AUTOSAR XML (schema 00048)
standard types defined: uint8, sint8
package /System
  system System: category=SYSTEM_EXTRACT
package /Ecus
  6 x ecu instance:
    Ecu0
      can communication controller CanCtrl0
      can communication connector Can0Conn: comm-controller=CanCtrl0
    Ecu1
      can communication controller CanCtrl1
      can communication connector Can1Conn: comm-controller=CanCtrl1
    Ecu2
    Ecu3
    EthServer
      ethernet communication controller EthCtrl
        coupling port EthCtrl_CouplingPort
      ethernet communication connector EthConn: category=WIRED, comm-controller=EthServer/EthCtrl
    EthClient
      ethernet communication controller EthCtrl
        coupling port EthCtrl_CouplingPort
      ethernet communication connector EthConn: category=WIRED, comm-controller=EthClient/EthCtrl
package /Units
  unit degC: display-name=degC
package /Transformers
  data transformation set E2E
    transformation technology E2E_0:
      buffer-properties={header-length=96, in-place=true}
      has-internal-state=true
      needs-original-data=false
      protocol=E2E
      end-to-end-transformation-description{max-delta-counter=1, max-error-state-init=0, max-error-state-invalid=0, max-error-state-valid=0, max-no-new-or-repeated-data=2, min-ok-state-init=1, min-ok-state-invalid=1, min-ok-state-valid=1, offset=0, profile-behavior=R-4--2, profile-name=PROFILE_04, upper-header-bits-to-shift=0, window-size-init=3, window-size-invalid=3, window-size-valid=3}
      transformer-class=SAFETY
      version=1.0.0
    transformation technology E2E_1:
      buffer-properties={header-length=24, in-place=true}
      has-internal-state=true
      needs-original-data=false
      protocol=E2E
      end-to-end-transformation-description{max-delta-counter=1, max-error-state-init=0, max-error-state-invalid=0, max-error-state-valid=0, max-no-new-or-repeated-data=2, min-ok-state-init=1, min-ok-state-invalid=1, min-ok-state-valid=1, offset=8, profile-behavior=R-4--2, profile-name=PROFILE_05, upper-header-bits-to-shift=8, window-size-init=3, window-size-invalid=3, window-size-valid=3}
      transformer-class=SAFETY
      version=1.0.0
package /Can0
  can cluster Can0: baudrate=500000, protocol-name=CAN
    can physical channel Can0Ch: comm-connectors=Can0Conn
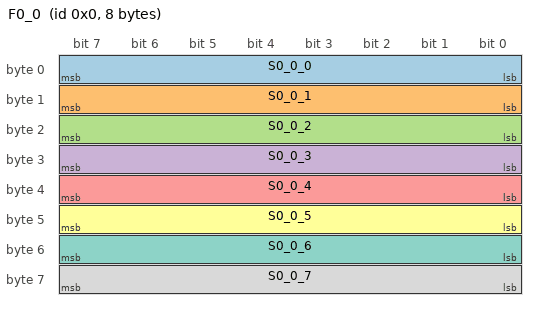
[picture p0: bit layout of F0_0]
      frame F0_0: id 0x0, frame-length=8, can-addressing-mode=STANDARD, can-frame-rx-behavior=CAN-20, can-frame-tx-behavior=CAN-20
        pdu P0_0: length=8, transmission-mode-true-timing=cyclic-timing=time-period=0.01
          signal S0_0_0: start 0, 8 bit, little-endian, data-type-policy=OVERRIDE, base-type=uint8, end-to-end-transformation-i-signal-props{transformer=E2E_0, data-ids=256}, compu {identical}, transfer-property=PENDING
          signal S0_0_1: start 8, 8 bit, little-endian, data-type-policy=OVERRIDE, base-type=uint8, compu {phys=raw*0.5-40 for raw 0..255}, range phys -40..87.5, unit=degC, transfer-property=PENDING
          signal S0_0_2: start 16, 8 bit, little-endian, data-type-policy=OVERRIDE, base-type=uint8, compu {0=Off, 1=On, 2=Error, 3=SNA}, transfer-property=PENDING
          signal S0_0_3: start 24, 8 bit, little-endian, data-type-policy=OVERRIDE, base-type=uint8, compu {phys=raw for raw 0..99, phys=raw*2-100 for raw 100..255}, transfer-property=PENDING
          signal S0_0_4: start 32, 8 bit, little-endian, data-type-policy=OVERRIDE, base-type=sint8, compu {phys=(1+2*raw)/(4+0.5*raw) for raw -128..127}, transfer-property=PENDING
          signal S0_0_5: start 40, 8 bit, little-endian, data-type-policy=OVERRIDE, base-type=uint8, compu {0=0, 1=10, 2=25, 3=60}, transfer-property=PENDING
          signal S0_0_6: start 48, 8 bit, little-endian, data-type-policy=OVERRIDE, base-type=uint8, compu {mask 1: 1=Left, mask 2: 2=Right, mask 4: 4=Hazard}, transfer-property=PENDING
          signal S0_0_7: start 56, 8 bit, little-endian, data-type-policy=OVERRIDE, base-type=uint8, compu {phys=raw*0.25 for raw 0..250, 254=Init, 255=SNA}, transfer-property=PENDING
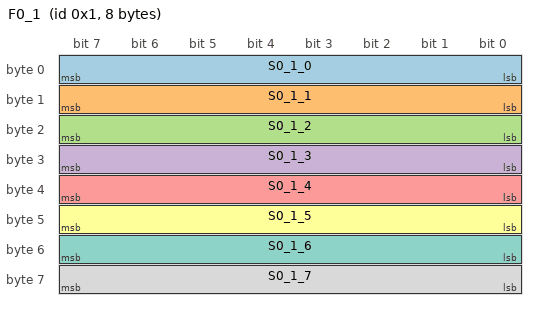
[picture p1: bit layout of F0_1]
      frame F0_1: id 0x1, frame-length=8, can-addressing-mode=STANDARD, can-frame-rx-behavior=CAN-20, can-frame-tx-behavior=CAN-20
        pdu P0_1: length=8, transmission-mode-true-timing=cyclic-timing=time-period=0.02
          signal S0_1_0: start 7, 8 bit, big-endian, data-type-policy=OVERRIDE, base-type=uint8, end-to-end-transformation-i-signal-props{transformer=E2E_1, data-ids=257}, compu {identical}, transfer-property=PENDING
          signal S0_1_1: start 15, 8 bit, big-endian, data-type-policy=OVERRIDE, base-type=uint8, compu {phys=raw*0.5-40 for raw 0..255}, range phys -40..87.5, unit=degC, transfer-property=PENDING
          signal S0_1_2: start 23, 8 bit, big-endian, data-type-policy=OVERRIDE, base-type=uint8, compu {0=Off, 1=On, 2=Error, 3=SNA}, transfer-property=PENDING
          signal S0_1_3: start 31, 8 bit, big-endian, data-type-policy=OVERRIDE, base-type=uint8, compu {phys=raw for raw 0..99, phys=raw*2-100 for raw 100..255}, transfer-property=PENDING
          signal S0_1_4: start 39, 8 bit, big-endian, data-type-policy=OVERRIDE, base-type=sint8, compu {phys=(1+2*raw)/(4+0.5*raw) for raw -128..127}, transfer-property=PENDING
          signal S0_1_5: start 47, 8 bit, big-endian, data-type-policy=OVERRIDE, base-type=uint8, compu {0=0, 1=10, 2=25, 3=60}, transfer-property=PENDING
          signal S0_1_6: start 55, 8 bit, big-endian, data-type-policy=OVERRIDE, base-type=uint8, compu {mask 1: 1=Left, mask 2: 2=Right, mask 4: 4=Hazard}, transfer-property=PENDING
          signal S0_1_7: start 63, 8 bit, big-endian, data-type-policy=OVERRIDE, base-type=uint8, compu {phys=raw*0.25 for raw 0..250, 254=Init, 255=SNA}, transfer-property=PENDING
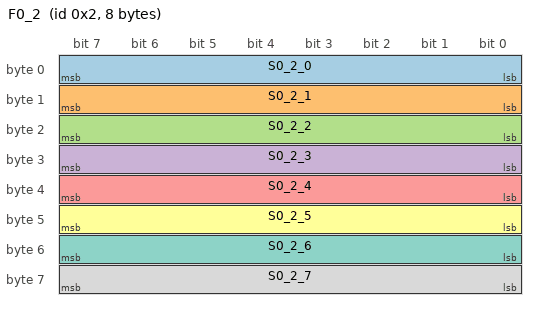
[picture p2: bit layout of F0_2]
      frame F0_2: id 0x2, frame-length=8, can-addressing-mode=STANDARD, can-frame-rx-behavior=CAN-20, can-frame-tx-behavior=CAN-20
        pdu P0_2: length=8, transmission-mode-true-timing=cyclic-timing=time-period=0.03
          signal S0_2_0: start 0, 8 bit, little-endian, data-type-policy=OVERRIDE, base-type=uint8, compu {identical}, transfer-property=PENDING
          signal S0_2_1: start 8, 8 bit, little-endian, data-type-policy=OVERRIDE, base-type=uint8, compu {phys=raw*0.5-40 for raw 0..255}, range phys -40..87.5, unit=degC, transfer-property=PENDING
          signal S0_2_2: start 16, 8 bit, little-endian, data-type-policy=OVERRIDE, base-type=uint8, compu {0=Off, 1=On, 2=Error, 3=SNA}, transfer-property=PENDING
          signal S0_2_3: start 24, 8 bit, little-endian, data-type-policy=OVERRIDE, base-type=uint8, compu {phys=raw for raw 0..99, phys=raw*2-100 for raw 100..255}, transfer-property=PENDING
          signal S0_2_4: start 32, 8 bit, little-endian, data-type-policy=OVERRIDE, base-type=sint8, compu {phys=(1+2*raw)/(4+0.5*raw) for raw -128..127}, transfer-property=PENDING
          signal S0_2_5: start 40, 8 bit, little-endian, data-type-policy=OVERRIDE, base-type=uint8, compu {0=0, 1=10, 2=25, 3=60}, transfer-property=PENDING
          signal S0_2_6: start 48, 8 bit, little-endian, data-type-policy=OVERRIDE, base-type=uint8, compu {mask 1: 1=Left, mask 2: 2=Right, mask 4: 4=Hazard}, transfer-property=PENDING
          signal S0_2_7: start 56, 8 bit, little-endian, data-type-policy=OVERRIDE, base-type=uint8, compu {phys=raw*0.25 for raw 0..250, 254=Init, 255=SNA}, transfer-property=PENDING
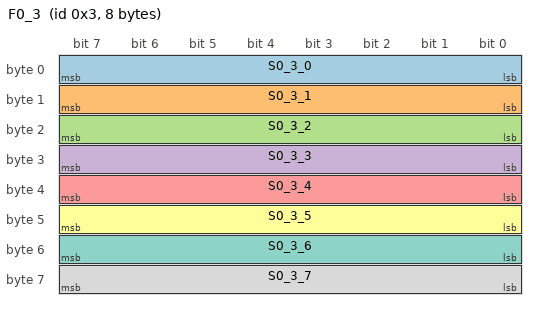
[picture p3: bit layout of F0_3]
      frame F0_3: id 0x3, frame-length=8, can-addressing-mode=STANDARD, can-frame-rx-behavior=CAN-20, can-frame-tx-behavior=CAN-20
        pdu P0_3: length=8, transmission-mode-true-timing=cyclic-timing=time-period=0.04
          signal S0_3_0: start 7, 8 bit, big-endian, data-type-policy=OVERRIDE, base-type=uint8, compu {identical}, transfer-property=PENDING
          signal S0_3_1: start 15, 8 bit, big-endian, data-type-policy=OVERRIDE, base-type=uint8, compu {phys=raw*0.5-40 for raw 0..255}, range phys -40..87.5, unit=degC, transfer-property=PENDING
          signal S0_3_2: start 23, 8 bit, big-endian, data-type-policy=OVERRIDE, base-type=uint8, compu {0=Off, 1=On, 2=Error, 3=SNA}, transfer-property=PENDING
          signal S0_3_3: start 31, 8 bit, big-endian, data-type-policy=OVERRIDE, base-type=uint8, compu {phys=raw for raw 0..99, phys=raw*2-100 for raw 100..255}, transfer-property=PENDING
          signal S0_3_4: start 39, 8 bit, big-endian, data-type-policy=OVERRIDE, base-type=sint8, compu {phys=(1+2*raw)/(4+0.5*raw) for raw -128..127}, transfer-property=PENDING
          signal S0_3_5: start 47, 8 bit, big-endian, data-type-policy=OVERRIDE, base-type=uint8, compu {0=0, 1=10, 2=25, 3=60}, transfer-property=PENDING
          signal S0_3_6: start 55, 8 bit, big-endian, data-type-policy=OVERRIDE, base-type=uint8, compu {mask 1: 1=Left, mask 2: 2=Right, mask 4: 4=Hazard}, transfer-property=PENDING
          signal S0_3_7: start 63, 8 bit, big-endian, data-type-policy=OVERRIDE, base-type=uint8, compu {phys=raw*0.25 for raw 0..250, 254=Init, 255=SNA}, transfer-property=PENDING
package /Can1
  can cluster Can1: baudrate=500000, protocol-name=CAN, can-fd-baudrate=2000000
    can physical channel Can1Ch: comm-connectors=Can1Conn
      frame F1_0: id 0x0, frame-length=64, can-addressing-mode=STANDARD, can-frame-rx-behavior=CAN-FD, can-frame-tx-behavior=CAN-FD
        pdu P1_0: length=8, transmission-mode-true-timing=cyclic-timing=time-period=0.01
          signal S1_0_0: start 0, 8 bit, little-endian, data-type-policy=OVERRIDE, base-type=uint8, compu {identical}, transfer-property=PENDING
          signal S1_0_1: start 8, 8 bit, little-endian, data-type-policy=OVERRIDE, base-type=uint8, compu {phys=raw*0.5-40 for raw 0..255}, range phys -40..87.5, unit=degC, transfer-property=PENDING
          signal S1_0_2: start 16, 8 bit, little-endian, data-type-policy=OVERRIDE, base-type=uint8, compu {0=Off, 1=On, 2=Error, 3=SNA}, transfer-property=PENDING
          signal S1_0_3: start 24, 8 bit, little-endian, data-type-policy=OVERRIDE, base-type=uint8, compu {phys=raw for raw 0..99, phys=raw*2-100 for raw 100..255}, transfer-property=PENDING
          signal S1_0_4: start 32, 8 bit, little-endian, data-type-policy=OVERRIDE, base-type=sint8, compu {phys=(1+2*raw)/(4+0.5*raw) for raw -128..127}, transfer-property=PENDING
          signal S1_0_5: start 40, 8 bit, little-endian, data-type-policy=OVERRIDE, base-type=uint8, compu {0=0, 1=10, 2=25, 3=60}, transfer-property=PENDING
          signal S1_0_6: start 48, 8 bit, little-endian, data-type-policy=OVERRIDE, base-type=uint8, compu {mask 1: 1=Left, mask 2: 2=Right, mask 4: 4=Hazard}, transfer-property=PENDING
          signal S1_0_7: start 56, 8 bit, little-endian, data-type-policy=OVERRIDE, base-type=uint8, compu {phys=raw*0.25 for raw 0..250, 254=Init, 255=SNA}, transfer-property=PENDING
      frame F1_1: id 0x10001, frame-length=64, can-addressing-mode=EXTENDED, can-frame-rx-behavior=CAN-FD, can-frame-tx-behavior=CAN-FD
        pdu P1_1: length=8, transmission-mode-true-timing=cyclic-timing=time-period=0.02
          signal S1_1_0: start 7, 8 bit, big-endian, data-type-policy=OVERRIDE, base-type=uint8, compu {identical}, transfer-property=PENDING
          signal S1_1_1: start 15, 8 bit, big-endian, data-type-policy=OVERRIDE, base-type=uint8, compu {phys=raw*0.5-40 for raw 0..255}, range phys -40..87.5, unit=degC, transfer-property=PENDING
          signal S1_1_2: start 23, 8 bit, big-endian, data-type-policy=OVERRIDE, base-type=uint8, compu {0=Off, 1=On, 2=Error, 3=SNA}, transfer-property=PENDING
          signal S1_1_3: start 31, 8 bit, big-endian, data-type-policy=OVERRIDE, base-type=uint8, compu {phys=raw for raw 0..99, phys=raw*2-100 for raw 100..255}, transfer-property=PENDING
          signal S1_1_4: start 39, 8 bit, big-endian, data-type-policy=OVERRIDE, base-type=sint8, compu {phys=(1+2*raw)/(4+0.5*raw) for raw -128..127}, transfer-property=PENDING
          signal S1_1_5: start 47, 8 bit, big-endian, data-type-policy=OVERRIDE, base-type=uint8, compu {0=0, 1=10, 2=25, 3=60}, transfer-property=PENDING
          signal S1_1_6: start 55, 8 bit, big-endian, data-type-policy=OVERRIDE, base-type=uint8, compu {mask 1: 1=Left, mask 2: 2=Right, mask 4: 4=Hazard}, transfer-property=PENDING
          signal S1_1_7: start 63, 8 bit, big-endian, data-type-policy=OVERRIDE, base-type=uint8, compu {phys=raw*0.25 for raw 0..250, 254=Init, 255=SNA}, transfer-property=PENDING
      frame F1_2: id 0x2, frame-length=64, can-addressing-mode=STANDARD, can-frame-rx-behavior=CAN-FD, can-frame-tx-behavior=CAN-FD
        pdu P1_2: length=8, transmission-mode-true-timing=cyclic-timing=time-period=0.03
          signal S1_2_0: start 0, 8 bit, little-endian, data-type-policy=OVERRIDE, base-type=uint8, compu {identical}, transfer-property=PENDING
          signal S1_2_1: start 8, 8 bit, little-endian, data-type-policy=OVERRIDE, base-type=uint8, compu {phys=raw*0.5-40 for raw 0..255}, range phys -40..87.5, unit=degC, transfer-property=PENDING
          signal S1_2_2: start 16, 8 bit, little-endian, data-type-policy=OVERRIDE, base-type=uint8, compu {0=Off, 1=On, 2=Error, 3=SNA}, transfer-property=PENDING
          signal S1_2_3: start 24, 8 bit, little-endian, data-type-policy=OVERRIDE, base-type=uint8, compu {phys=raw for raw 0..99, phys=raw*2-100 for raw 100..255}, transfer-property=PENDING
          signal S1_2_4: start 32, 8 bit, little-endian, data-type-policy=OVERRIDE, base-type=sint8, compu {phys=(1+2*raw)/(4+0.5*raw) for raw -128..127}, transfer-property=PENDING
          signal S1_2_5: start 40, 8 bit, little-endian, data-type-policy=OVERRIDE, base-type=uint8, compu {0=0, 1=10, 2=25, 3=60}, transfer-property=PENDING
          signal S1_2_6: start 48, 8 bit, little-endian, data-type-policy=OVERRIDE, base-type=uint8, compu {mask 1: 1=Left, mask 2: 2=Right, mask 4: 4=Hazard}, transfer-property=PENDING
          signal S1_2_7: start 56, 8 bit, little-endian, data-type-policy=OVERRIDE, base-type=uint8, compu {phys=raw*0.25 for raw 0..250, 254=Init, 255=SNA}, transfer-property=PENDING
      frame F1_3: id 0x10003, frame-length=64, can-addressing-mode=EXTENDED, can-frame-rx-behavior=CAN-FD, can-frame-tx-behavior=CAN-FD
        pdu P1_3: length=8, transmission-mode-true-timing=cyclic-timing=time-period=0.04
          signal S1_3_0: start 7, 8 bit, big-endian, data-type-policy=OVERRIDE, base-type=uint8, compu {identical}, transfer-property=PENDING
          signal S1_3_1: start 15, 8 bit, big-endian, data-type-policy=OVERRIDE, base-type=uint8, compu {phys=raw*0.5-40 for raw 0..255}, range phys -40..87.5, unit=degC, transfer-property=PENDING
          signal S1_3_2: start 23, 8 bit, big-endian, data-type-policy=OVERRIDE, base-type=uint8, compu {0=Off, 1=On, 2=Error, 3=SNA}, transfer-property=PENDING
          signal S1_3_3: start 31, 8 bit, big-endian, data-type-policy=OVERRIDE, base-type=uint8, compu {phys=raw for raw 0..99, phys=raw*2-100 for raw 100..255}, transfer-property=PENDING
          signal S1_3_4: start 39, 8 bit, big-endian, data-type-policy=OVERRIDE, base-type=sint8, compu {phys=(1+2*raw)/(4+0.5*raw) for raw -128..127}, transfer-property=PENDING
          signal S1_3_5: start 47, 8 bit, big-endian, data-type-policy=OVERRIDE, base-type=uint8, compu {0=0, 1=10, 2=25, 3=60}, transfer-property=PENDING
          signal S1_3_6: start 55, 8 bit, big-endian, data-type-policy=OVERRIDE, base-type=uint8, compu {mask 1: 1=Left, mask 2: 2=Right, mask 4: 4=Hazard}, transfer-property=PENDING
          signal S1_3_7: start 63, 8 bit, big-endian, data-type-policy=OVERRIDE, base-type=uint8, compu {phys=raw*0.25 for raw 0..250, 254=Init, 255=SNA}, transfer-property=PENDING
      frame CF0: id 0x1F000000, frame-length=64, can-addressing-mode=EXTENDED, can-frame-rx-behavior=CAN-FD, can-frame-tx-behavior=CAN-FD
        container i pdu C0: length=64, contained-pdu-triggering=[PT_C0_0, PT_C0_1], header-type=SHORT-HEADER, rx-accept-contained-i-pdu=ACCEPT-ALL
      frame SF0: id 0x1E000000, frame-length=16, can-addressing-mode=EXTENDED, can-frame-rx-behavior=CAN-FD, can-frame-tx-behavior=CAN-FD
        secured i pdu SEC0: length=12, payload=PT_SP0, secure-communication-props={auth-info-tx-length=24, data-id=0, freshness-value-tx-length=8}
      frame TF0: id 0x7E0, frame-length=8, can-addressing-mode=STANDARD, can-frame-rx-behavior=CAN-20, can-frame-tx-behavior=CAN-20
        n pdu TPN0: length=8
      pdu triggering PT_C0_0: pdu=C0_0
      pdu triggering PT_C0_1: pdu=C0_1
      pdu triggering PT_SP0: pdu=SP0
package /Can1/Pdus
  pdu C0_0: length=8, contained-i-pdu-props=header-id-short-header=1
    signal C0_0_0: start 0, 8 bit, little-endian, data-type-policy=OVERRIDE, base-type=uint8, compu {phys=raw*0.5-40 for raw 0..255}, range phys -40..87.5, unit=degC, transfer-property=PENDING
    signal C0_0_1: start 8, 8 bit, little-endian, data-type-policy=OVERRIDE, base-type=uint8, compu {phys=raw*0.5-40 for raw 0..255}, range phys -40..87.5, unit=degC, transfer-property=PENDING
  pdu C0_1: length=8, contained-i-pdu-props=header-id-short-header=2
    signal C0_1_0: start 0, 8 bit, little-endian, data-type-policy=OVERRIDE, base-type=uint8, compu {phys=raw*0.5-40 for raw 0..255}, range phys -40..87.5, unit=degC, transfer-property=PENDING
    signal C0_1_1: start 8, 8 bit, little-endian, data-type-policy=OVERRIDE, base-type=uint8, compu {phys=raw*0.5-40 for raw 0..255}, range phys -40..87.5, unit=degC, transfer-property=PENDING
  pdu SP0: length=8
    signal SP0_0: start 0, 8 bit, little-endian, data-type-policy=OVERRIDE, base-type=uint8, compu {phys=raw*0.5-40 for raw 0..255}, range phys -40..87.5, unit=degC, transfer-property=PENDING
    signal SP0_1: start 8, 8 bit, little-endian, data-type-policy=OVERRIDE, base-type=uint8, compu {phys=raw*0.5-40 for raw 0..255}, range phys -40..87.5, unit=degC, transfer-property=PENDING
  pdu TP0: length=20
    signal TP0_0: start 0, 8 bit, little-endian, data-type-policy=OVERRIDE, base-type=uint8, compu {identical}, transfer-property=PENDING
    signal TP0_1: start 56, 8 bit, little-endian, data-type-policy=OVERRIDE, base-type=uint8, compu {identical}, transfer-property=PENDING
    signal TP0_2: start 96, 8 bit, little-endian, data-type-policy=OVERRIDE, base-type=uint8, compu {identical}, transfer-property=PENDING
    signal TP0_3: start 152, 8 bit, little-endian, data-type-policy=OVERRIDE, base-type=uint8, compu {identical}, transfer-property=PENDING
package /CanTp
  can tp config CanTp: communication-cluster=Can1
    can tp address TpRxAddr: tp-address=16
    can tp channel TpCh: channel-id=0, channel-mode=HALF-DUPLEX-MODE
    can-tp-connection addressing-format=EXTENDED, can-tp-channel=TpCh, data-pdu=TPN0, padding-activation=true, receiver=TpRx, tp-sdu=TP0:
      ident TP0
    can tp node TpRx: tp-address=TpRxAddr
package /Ethernet
  ethernet cluster Eth
    ethernet physical channel EthCh: category=WIRED, comm-connectors=[EthServer/EthConn, EthClient/EthConn]
      pdu triggering PT_Ev_0_{0..9}: pdu=Ev_0_{0..9}
      pdu triggering PT_Req_0_{0..4}: pdu=Req_0_{0..4}
      pdu triggering PT_Ev_1_{0..9}: pdu=Ev_1_{0..9}
      pdu triggering PT_Req_1_{0..4}: pdu=Req_1_{0..4}
      network endpoint NE_Srv0: network-endpoint-addresses=ipv-4-configuration={ipv-4-address=10.0.0.1, ipv-4-address-source=FIXED, network-mask=255.255.0.0}
      network endpoint NE_Cli: network-endpoint-addresses=ipv-4-configuration={ipv-4-address=10.1.0.1, ipv-4-address-source=FIXED, network-mask=255.255.0.0}
      so-ad-config:
        socket address SA_Srv0: connector=EthServer/EthConn
          application endpoint SA_Srv0_AE: network-endpoint=NE_Srv0, tp-configuration=udp-tp=udp-tp-port=port-number=30501
        socket address SA_Cli0: connector=EthClient/EthConn
          application endpoint SA_Cli0_AE: network-endpoint=NE_Cli, tp-configuration=udp-tp=udp-tp-port=port-number=30501
        socket address SA_Srv1: connector=EthServer/EthConn
          application endpoint SA_Srv1_AE: network-endpoint=NE_Srv0, tp-configuration=udp-tp=udp-tp-port=port-number=30502
  socket connection ipdu identifier set SoConIds
    30 x so con i pdu identifier:
      Ev_0_0: header-id=268468225, pdu-triggering=PT_Ev_0_0
      Ev_0_1: header-id=268468226, pdu-triggering=PT_Ev_0_1
      Ev_0_2: header-id=268468227, pdu-triggering=PT_Ev_0_2
      Ev_0_3: header-id=268468228, pdu-triggering=PT_Ev_0_3
      Ev_0_4: header-id=268468229, pdu-triggering=PT_Ev_0_4
      Ev_0_5: header-id=268468230, pdu-triggering=PT_Ev_0_5
      Ev_0_6: header-id=268468231, pdu-triggering=PT_Ev_0_6
      Ev_0_7: header-id=268468232, pdu-triggering=PT_Ev_0_7
      Ev_0_8: header-id=268468233, pdu-triggering=PT_Ev_0_8
      Ev_0_9: header-id=268468234, pdu-triggering=PT_Ev_0_9
      Req_0_0: header-id=268435457, pdu-triggering=PT_Req_0_0
      Req_0_1: header-id=268435458, pdu-triggering=PT_Req_0_1
      Req_0_2: header-id=268435459, pdu-triggering=PT_Req_0_2
      Req_0_3: header-id=268435460, pdu-triggering=PT_Req_0_3
      Req_0_4: header-id=268435461, pdu-triggering=PT_Req_0_4
      Ev_1_0: header-id=268533761, pdu-triggering=PT_Ev_1_0
      Ev_1_1: header-id=268533762, pdu-triggering=PT_Ev_1_1
      Ev_1_2: header-id=268533763, pdu-triggering=PT_Ev_1_2
      Ev_1_3: header-id=268533764, pdu-triggering=PT_Ev_1_3
      Ev_1_4: header-id=268533765, pdu-triggering=PT_Ev_1_4
      Ev_1_5: header-id=268533766, pdu-triggering=PT_Ev_1_5
      Ev_1_6: header-id=268533767, pdu-triggering=PT_Ev_1_6
      Ev_1_7: header-id=268533768, pdu-triggering=PT_Ev_1_7
      Ev_1_8: header-id=268533769, pdu-triggering=PT_Ev_1_8
      Ev_1_9: header-id=268533770, pdu-triggering=PT_Ev_1_9
      Req_1_0: header-id=268500993, pdu-triggering=PT_Req_1_0
      Req_1_1: header-id=268500994, pdu-triggering=PT_Req_1_1
      Req_1_2: header-id=268500995, pdu-triggering=PT_Req_1_2
      Req_1_3: header-id=268500996, pdu-triggering=PT_Req_1_3
      Req_1_4: header-id=268500997, pdu-triggering=PT_Req_1_4
package /Ethernet/Pdus
  pdu Ev_0_{0..9}: length=32
  pdu Req_0_{0..4}: length=32
  pdu Ev_1_{0..9}: length=32
  pdu Req_1_{0..4}: length=32
package /ServiceInstances
  service instance collection set Services
    provided service instance PSI_0: major-version=1, instance-identifier=1, local-unicast-addresss=SA_Srv0_AE, minor-version=0, service-identifier=4096
      method-activation-routing-groups:
        pdu activation routing group MRG: i-pdu-identifier-udp=[Req_0_0, Req_0_1, Req_0_2, Req_0_3, Req_0_4]
      event handler EH1: event-group-identifier=1
        pdu activation routing group RG: event-group-control-type=ACTIVATION-UNICAST, i-pdu-identifier-udp=[Ev_0_0, Ev_0_1, Ev_0_2, Ev_0_3, Ev_0_4]
      event handler EH2: event-group-identifier=2
        pdu activation routing group RG: event-group-control-type=ACTIVATION-UNICAST, i-pdu-identifier-udp=[Ev_0_5, Ev_0_6, Ev_0_7, Ev_0_8, Ev_0_9]
    consumed service instance CSI_0: major-version=1, instance-identifier=1, local-unicast-addresss=SA_Cli0_AE, minor-version=0, service-identifier=4096
      consumed event group CEG1: event-group-identifier=1
      consumed event group CEG2: event-group-identifier=2
    provided service instance PSI_1: major-version=1, instance-identifier=1, local-unicast-addresss=SA_Srv1_AE, minor-version=0, service-identifier=4097
      method-activation-routing-groups:
        pdu activation routing group MRG: i-pdu-identifier-udp=[Req_1_0, Req_1_1, Req_1_2, Req_1_3, Req_1_4]
      event handler EH1: event-group-identifier=1
        pdu activation routing group RG: event-group-control-type=ACTIVATION-UNICAST, i-pdu-identifier-udp=[Ev_1_0, Ev_1_1, Ev_1_2, Ev_1_3, Ev_1_4]
      event handler EH2: event-group-identifier=2
        pdu activation routing group RG: event-group-control-type=ACTIVATION-UNICAST, i-pdu-identifier-udp=[Ev_1_5, Ev_1_6, Ev_1_7, Ev_1_8, Ev_1_9]
package /ServiceInterfaces
  service interface SI_0
    events:
      10 x data:
        ev{0..9}
    methods:
      5 x operation:
        m{0..4}
  service interface SI_1
    events:
      10 x data:
        ev{0..9}
    methods:
      5 x operation:
        m{0..4}
package /Deployments
  someip service interface deployment DEP_0: service-interface=SI_0, service-interface-id=4096
    10 x someip event deployment:
      ev0: event=SI_0/ev0, event-id=32769
      ev1: event=SI_0/ev1, event-id=32770
      ev2: event=SI_0/ev2, event-id=32771
      ev3: event=SI_0/ev3, event-id=32772
      ev4: event=SI_0/ev4, event-id=32773
      ev5: event=SI_0/ev5, event-id=32774
      ev6: event=SI_0/ev6, event-id=32775
      ev7: event=SI_0/ev7, event-id=32776
      ev8: event=SI_0/ev8, event-id=32777
      ev9: event=SI_0/ev9, event-id=32778
    5 x someip method deployment:
      m0: method=SI_0/m0, method-id=1
      m1: method=SI_0/m1, method-id=2
      m2: method=SI_0/m2, method-id=3
      m3: method=SI_0/m3, method-id=4
      m4: method=SI_0/m4, method-id=5
    someip event group eg1: event-group-id=1, event=[DEP_0/ev0, DEP_0/ev1, DEP_0/ev2, DEP_0/ev3, DEP_0/ev4]
    someip event group eg2: event-group-id=2, event=[DEP_0/ev5, DEP_0/ev6, DEP_0/ev7, DEP_0/ev8, DEP_0/ev9]
  someip service interface deployment DEP_1: service-interface=SI_1, service-interface-id=4097
    10 x someip event deployment:
      ev0: event=SI_1/ev0, event-id=32769
      ev1: event=SI_1/ev1, event-id=32770
      ev2: event=SI_1/ev2, event-id=32771
      ev3: event=SI_1/ev3, event-id=32772
      ev4: event=SI_1/ev4, event-id=32773
      ev5: event=SI_1/ev5, event-id=32774
      ev6: event=SI_1/ev6, event-id=32775
      ev7: event=SI_1/ev7, event-id=32776
      ev8: event=SI_1/ev8, event-id=32777
      ev9: event=SI_1/ev9, event-id=32778
    5 x someip method deployment:
      m0: method=SI_1/m0, method-id=1
      m1: method=SI_1/m1, method-id=2
      m2: method=SI_1/m2, method-id=3
      m3: method=SI_1/m3, method-id=4
      m4: method=SI_1/m4, method-id=5
    someip event group eg1: event-group-id=1, event=[DEP_1/ev0, DEP_1/ev1, DEP_1/ev2, DEP_1/ev3, DEP_1/ev4]
    someip event group eg2: event-group-id=2, event=[DEP_1/ev5, DEP_1/ev6, DEP_1/ev7, DEP_1/ev8, DEP_1/ev9]
